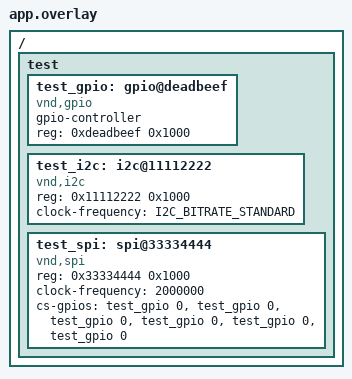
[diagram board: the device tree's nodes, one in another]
/*
 * Copyright (c) 2024 Cirrus Logic, Inc.
 * SPDX-License-Identifier: Apache-2.0
 */

#include <zephyr/dt-bindings/i2c/i2c.h>

/ {
	test {
		#address-cells = <1>;
		#size-cells = <1>;

		test_gpio: gpio@deadbeef {
			compatible = "vnd,gpio";
			gpio-controller;
			reg = <0xdeadbeef 0x1000>;
			#gpio-cells = <0x2>;
			status = "okay";
		};

		test_i2c: i2c@11112222 {
			#address-cells = <1>;
			#size-cells = <0>;
			compatible = "vnd,i2c";
			reg = <0x11112222 0x1000>;
			status = "okay";
			clock-frequency = <I2C_BITRATE_STANDARD>;

			#include "i2c.dtsi"
		};

		test_spi: spi@33334444 {
			#address-cells = <1>;
			#size-cells = <0>;
			compatible = "vnd,spi";
			reg = <0x33334444 0x1000>;
			status = "okay";
			clock-frequency = <2000000>;

			/* one entry for every devices at spi.dtsi */
			cs-gpios = <&test_gpio 0 0>,
				   <&test_gpio 0 0>,
				   <&test_gpio 0 0>,
				   <&test_gpio 0 0>,
				   <&test_gpio 0 0>,
				   <&test_gpio 0 0>;

			#include "spi.dtsi"
		};
	};
};
